# MK30D7 register map
File version: 1.6
Registers are 32-bit, read-write, reset 0x0 unless marked. A register's access mark holds for its fields unless they carry their own. Offsets are from the block's base; [hi:lo] are bit positions; {n}, {i} and the like mark numbered series.

## PDB0 — Programmable Delay Block
Base 0x40036000; register names take the prefix PDB0_
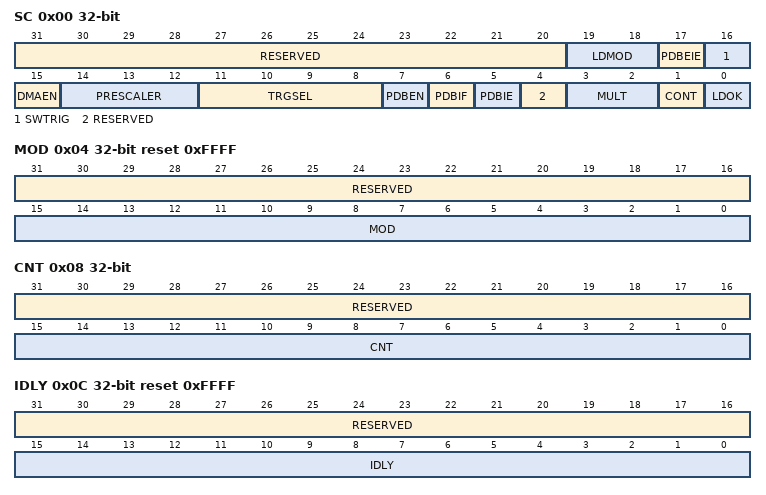
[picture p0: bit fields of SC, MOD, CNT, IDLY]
0x00 SC access per field — Status and Control Register
  [31:20] RESERVED ro
  [19:18] LDMOD rw — Load Mode Select
    0=The internal registers are loaded with the values from their buffers immediately after 1 is written to LDOK; 1=The internal registers are loaded with the values from their buffers when the PDB counter reaches the MOD register value after 1 is written to LDOK; 2=The internal registers are loaded with the values from their buffers when a trigger input event is detected after 1 is written to LDOK; 3=The internal registers are loaded with the values from their buffers when either the PDB counter reaches the MOD register value or a trigger input event is detected, after 1 is written to LDOK
  [17] PDBEIE rw — PDB Sequence Error Interrupt Enable
    0=PDB sequence error interrupt disabled; 1=PDB sequence error interrupt enabled
  [16] SWTRIG wo — Software Trigger
  [15] DMAEN rw — DMA Enable
    0=DMA disabled; 1=DMA enabled
  [14:12] PRESCALER rw — Prescaler Divider Select
    0=Counting uses the peripheral clock divided by multiplication factor selected by MULT; 1=Counting uses the peripheral clock divided by twice of the multiplication factor selected by MULT; 2=Counting uses the peripheral clock divided by four times of the multiplication factor selected by MULT; 3=Counting uses the peripheral clock divided by eight times of the multiplication factor selected by MULT; 4=Counting uses the peripheral clock divided by 16 times of the multiplication factor selected by MULT; 5=Counting uses the peripheral clock divided by 32 times of the multiplication factor selected by MULT; 6=Counting uses the peripheral clock divided by 64 times of the multiplication factor selected by MULT; 7=Counting uses the peripheral clock divided by 128 times of the multiplication factor selected by MULT
  [11:8] TRGSEL rw — Trigger Input Source Select
    {v}=Trigger-In {v} is selected (v=0..14); 15=Software trigger is selected
  [7] PDBEN rw — PDB Enable
    0=PDB disabled. Counter is off.; 1=PDB enabled
  [6] PDBIF rw — PDB Interrupt Flag
  [5] PDBIE rw — PDB Interrupt Enable.
    0=PDB interrupt disabled; 1=PDB interrupt enabled
  [4] RESERVED ro
  [3:2] MULT rw — Multiplication Factor Select for Prescaler
    0=Multiplication factor is 1; 1=Multiplication factor is 10; 2=Multiplication factor is 20; 3=Multiplication factor is 40
  [1] CONT rw — Continuous Mode Enable
    0=PDB operation in One-Shot mode; 1=PDB operation in Continuous mode
  [0] LDOK rw — Load OK
0x04 MOD access per field reset 0xFFFF — Modulus Register
  [31:16] RESERVED ro
  [15:0] MOD rw — PDB Modulus.
0x08 CNT ro — Counter Register
  [31:16] RESERVED
  [15:0] CNT — PDB Counter
0x0C IDLY access per field reset 0xFFFF — Interrupt Delay Register
  [31:16] RESERVED ro
  [15:0] IDLY rw — PDB Interrupt Delay
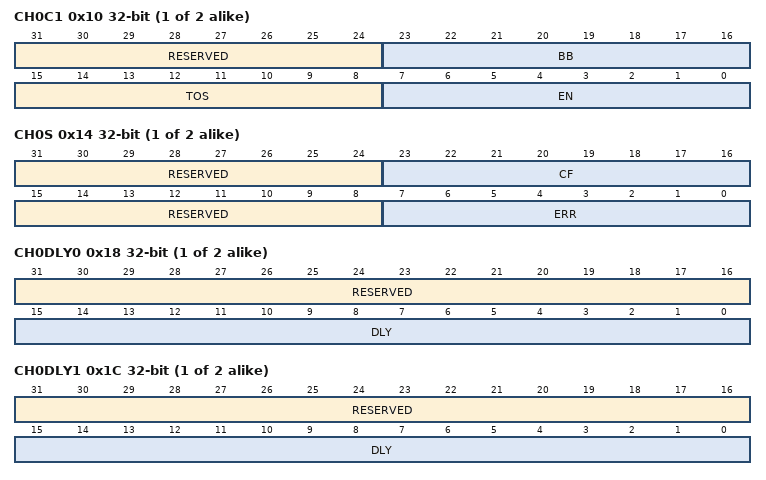
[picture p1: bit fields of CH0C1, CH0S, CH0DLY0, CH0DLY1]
{0x10+0x28*i} CH{i}C1 (i=0..1) access per field — Channel n Control Register 1
  [31:24] RESERVED ro
  [23:16] BB rw — PDB Channel Pre-Trigger Back-to-Back Operation Enable
    0=PDB channel's corresponding pre-trigger back-to-back operation disabled; 1=PDB channel's corresponding pre-trigger back-to-back operation enabled
  [15:8] TOS rw — PDB Channel Pre-Trigger Output Select
    0=PDB channel's corresponding pre-trigger is in bypassed mode. The pre-trigger asserts one peripheral clock cycle after a rising edge is detected on selected trigger input source or software trigger is selected and SWTRIG is written with 1.; 1=PDB channel's corresponding pre-trigger asserts when the counter reaches the channel delay register plus one peripheral clock cycle after a rising edge is detected on selected trigger input source or software trigger is selected and SETRIG is written with 1
  [7:0] EN rw — PDB Channel Pre-Trigger Enable
    0=PDB channel's corresponding pre-trigger disabled; 1=PDB channel's corresponding pre-trigger enabled
{0x14+0x28*i} CH{i}S (i=0..1) access per field — Channel n Status Register
  [31:24] RESERVED ro
  [23:16] CF rw — PDB Channel Flags
  [15:8] RESERVED ro
  [7:0] ERR rw — PDB Channel Sequence Error Flags
    0=Sequence error not detected on PDB channel's corresponding pre-trigger; 1=Sequence error detected on PDB channel's corresponding pre-trigger. ADCn block can be triggered for a conversion by one pre-trigger from PDB channel n. When one conversion, which is triggered by one of the pre-triggers from PDB channel n, is in progress, new trigger from PDB channel's corresponding pre-trigger m cannot be accepted by ADCn, and ERR[m] is set. Writing 1's to clear the sequence error flags.
{0x18+0x28*i} CH{i}DLY0 (i=0..1) access per field — Channel n Delay 0 Register
  [31:16] RESERVED ro
  [15:0] DLY rw — PDB Channel Delay
{0x1C+0x28*i} CH{i}DLY1 (i=0..1) access per field — Channel n Delay 1 Register
  [31:16] RESERVED ro
  [15:0] DLY rw — PDB Channel Delay
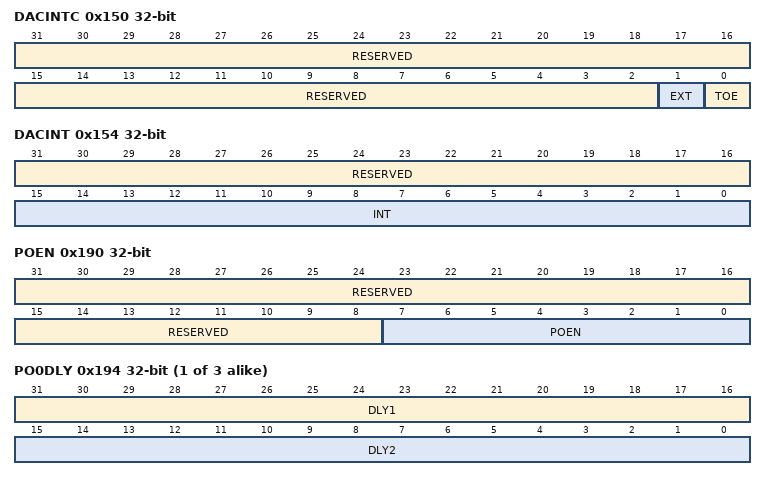
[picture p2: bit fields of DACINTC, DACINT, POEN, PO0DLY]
0x150 DACINTC access per field — DAC Interval Trigger n Control Register
  [31:2] RESERVED ro
  [1] EXT rw — DAC External Trigger Input Enable
    0=DAC external trigger input disabled. DAC interval counter is reset and started counting when a rising edge is detected on selected trigger input source or software trigger is selected and SWTRIG is written with 1.; 1=DAC external trigger input enabled. DAC interval counter is bypassed and DAC external trigger input triggers the DAC interval trigger.
  [0] TOE rw — DAC Interval Trigger Enable
    0=DAC interval trigger disabled; 1=DAC interval trigger enabled
0x154 DACINT access per field — DAC Interval n Register
  [31:16] RESERVED ro
  [15:0] INT rw — DAC Interval
0x190 POEN access per field — Pulse-Out n Enable Register
  [31:8] RESERVED ro
  [7:0] POEN rw — PDB Pulse-Out Enable
    0=PDB Pulse-Out disabled; 1=PDB Pulse-Out enabled
{0x194+4i} PO{i}DLY (i=0..2) — Pulse-Out n Delay Register
  [31:16] DLY1 — PDB Pulse-Out Delay 1
  [15:0] DLY2 — PDB Pulse-Out Delay 2
